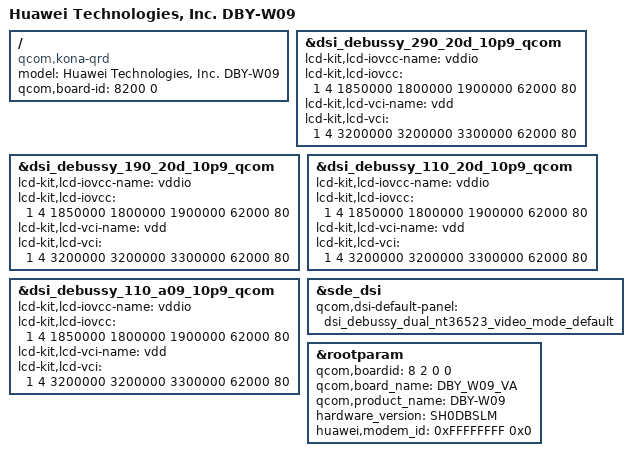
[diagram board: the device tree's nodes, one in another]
/dts-v1/;
/plugin/;

#include "../../common/common.dtsi"
#include "huawei-lcd.dtsi"
#include "huawei_tp.dtsi"
#include "huawei-audio.dtsi"
#include "huawei_wifi.dtsi"
#include "huawei_dev_detect.dtsi"
#include "huawei_antenna_board_detect.dtsi"
#include "huawei-vibrator.dtsi"
#include "huawei_pcie.dtsi"
#include "huawei_camera.dtsi"
#include "huawei-sensor.dtsi"
#include "huawei_wifionly.dtsi"
#include "huawei_led.dtsi"
#include "../common/huawei_charger.dtsi"
#include "../common/huawei_usb.dtsi"
#include "../common/huawei_btkb_led.dtsi"
/ {
    /* bsp_replace_info @ model = "Huawei Technologies, Inc. %product_name%"; */
    model = "Huawei Technologies, Inc. DBY-W09";
    compatible = "qcom,kona-qrd", "qcom,kona", "qcom,qrd";
    /* bsp_replace_info @ qcom,board-id = <%boardid% 0>; */
    qcom,board-id = <8200 0>;
};

&dsi_debussy_290_20d_10p9_qcom {
	lcd-kit,lcd-iovcc-name = "vddio";
	lcd-kit,lcd-iovcc = <1 4 1850000 1800000 1900000 62000 80>;
	lcd-kit,lcd-vci-name = "vdd";
	lcd-kit,lcd-vci = <1 4 3200000 3200000 3300000 62000 80>;
};

&dsi_debussy_190_20d_10p9_qcom {
	lcd-kit,lcd-iovcc-name = "vddio";
	lcd-kit,lcd-iovcc = <1 4 1850000 1800000 1900000 62000 80>;
	lcd-kit,lcd-vci-name = "vdd";
	lcd-kit,lcd-vci = <1 4 3200000 3200000 3300000 62000 80>;
};

&dsi_debussy_110_20d_10p9_qcom {
        lcd-kit,lcd-iovcc-name = "vddio";
        lcd-kit,lcd-iovcc = <1 4 1850000 1800000 1900000 62000 80>;
        lcd-kit,lcd-vci-name = "vdd";
        lcd-kit,lcd-vci = <1 4 3200000 3200000 3300000 62000 80>;
};

&dsi_debussy_110_a09_10p9_qcom {
        lcd-kit,lcd-iovcc-name = "vddio";
        lcd-kit,lcd-iovcc = <1 4 1850000 1800000 1900000 62000 80>;
        lcd-kit,lcd-vci-name = "vdd";
        lcd-kit,lcd-vci = <1 4 3200000 3200000 3300000 62000 80>;
};
&sde_dsi {
	qcom,dsi-default-panel = <&dsi_debussy_dual_nt36523_video_mode_default>;
};
&rootparam {
    /* bsp_replace_info @ qcom,boardid = <%boardid_split%>; */
    /* auto_key_info @ name: boardid type: uint32 default: 0 */
    qcom,boardid = <8 2 0 0>;
    /* bsp_replace_info @ qcom,board_name = "%board_name%"; */
    qcom,board_name = "DBY_W09_VA";
    /* bsp_replace_info @ qcom,product_name = "%product_name%"; */
    qcom,product_name = "DBY-W09";
    /* bsp_replace_info @ hardware_version = "%hardware_version%"; */
    hardware_version = "SH0DBSLM";
    /* bsp_replace_info @ huawei,modem_id = <%modem_id% 0x0>; */
    huawei,modem_id = <0xFFFFFFFF 0x0>;
};
